VERSION "1.2"

CM_ "TM-630 for Truma interface and Onan Generator
Author: Damiano Liviero
for Winnebago Industries Inc.
";

NS_ :

BS_:
BU_:

CM_ "EF64";
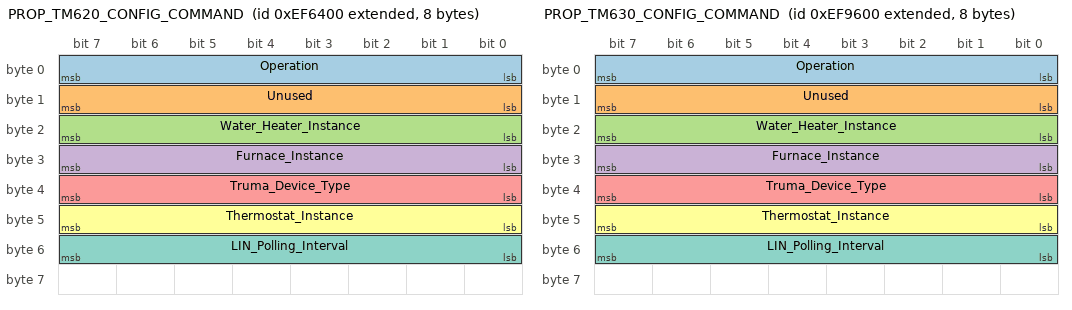
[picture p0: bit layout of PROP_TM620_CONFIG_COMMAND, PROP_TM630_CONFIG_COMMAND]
BO_ 2163172352 PROP_TM620_CONFIG_COMMAND: 8  Vector__XXX
    SG_ Operation:        0|8@1+  (1,0)   [0|255] ""    Vector__XXX
    SG_ Unused:        8|8@1+  (1,0)   [0|255] ""    Vector__XXX
    SG_ Water_Heater_Instance:        16|8@1+  (1,0)   [0|255] ""    Vector__XXX
    SG_ Furnace_Instance:        24|8@1+  (1,0)   [0|255] ""    Vector__XXX
    SG_ Truma_Device_Type:        32|8@1+  (1,0)   [0|255] ""    Vector__XXX
    SG_ Thermostat_Instance:        40|8@1+  (1,0)   [0|255] ""    Vector__XXX
    SG_ LIN_Polling_Interval:        48|8@1+  (1,0)   [0|255] ""    Vector__XXX

    50 "always use"
    255 "Data Invalid";

    255 "Data Invalid";

    255 "Data Invalid";

    255 "Data Invalid";

    0 "AquaGo/VarioHeat"
    1 "Combi"
    255 "Data Invalid";

    255 "Data Invalid";

    1 "100ms"
    2 "200ms"
    3 "300ms"
    4 "400ms"
    5 "500ms"
    255 "Data Invalid";

CM_ "EF96";
BO_ 2163185152 PROP_TM630_CONFIG_COMMAND: 8  Vector__XXX
    SG_ Operation:        0|8@1+  (1,0)   [0|255] ""    Vector__XXX
    SG_ Unused:        8|8@1+  (1,0)   [0|255] ""    Vector__XXX
    SG_ Water_Heater_Instance:        16|8@1+  (1,0)   [0|255] ""    Vector__XXX
    SG_ Furnace_Instance:        24|8@1+  (1,0)   [0|255] ""    Vector__XXX
    SG_ Truma_Device_Type:        32|8@1+  (1,0)   [0|255] ""    Vector__XXX
    SG_ Thermostat_Instance:        40|8@1+  (1,0)   [0|255] ""    Vector__XXX
    SG_ LIN_Polling_Interval:        48|8@1+  (1,0)   [0|255] ""    Vector__XXX

    50 "always use"
    255 "Data Invalid";

    255 "Data Invalid";

    255 "Data Invalid";

    255 "Data Invalid";

    0 "AquaGo/VarioHeat"
    1 "Combi"
    255 "Data Invalid";

    255 "Data Invalid";

    1 "100ms"
    2 "200ms"
    3 "300ms"
    4 "400ms"
    5 "500ms"
    255 "Data Invalid";

CM_ "EF44";
BO_ 2163164160 PROP_TM620_CONFIG_STATUS: 8  Vector__XXX
    SG_ Operation:
        0|8@1+  (1,0)   [0|255] ""    Vector__XXX
    SG_ Unused:
        8|8@1+  (1,0)   [0|255] ""    Vector__XXX
    SG_ Water_Heater_Instance:
        16|8@1+  (1,0)   [0|255] ""    Vector__XXX
    SG_ Furnace_Instance:
        24|8@1+  (1,0)   [0|255] ""    Vector__XXX
    SG_ Truma_Device_Type:
        32|8@1+  (1,0)   [0|255] ""    Vector__XXX
    SG_ Thermostat_Instance:
        40|8@1+  (1,0)   [0|255] ""    Vector__XXX
    SG_ LIN_Polling_Interval:
        48|8@1+  (1,0)   [0|255] ""    Vector__XXX
    SG_ LIN_Bus_Connection:
        56|2@1+  (1,0)   [0|3] ""    Vector__XXX
    SG_ Truma_Control_Panel_Status:
        58|2@1+  (1,0)   [0|3] ""    Vector__XXX
    SG_ Truma_Water_Heater_Error:
        60|2@1+  (1,0)   [0|3] ""    Vector__XXX
    SG_ Truma_Furnace_Error:
        62|2@1+  (1,0)   [0|3] ""    Vector__XXX

    51 "Always"
    255 "Data Invalid";

    255 "Data Invalid";

    255 "Data Invalid";

    255 "Data Invalid";

    0 "AquaGo/VarioHeat"
    1 "Combi"
    255 "Data Invalid";

    255 "Data Invalid";

    1 "100ms"
    2 "200ms"
    3 "300ms"
    4 "400ms"
    5 "500ms"
    255 "Data Invalid";

    0 "No"
    1 "Connected"
    3 "Data Invalid";

    0 "Not Busy"
    1 "Busy"
    3 "Data Invalid";

    0 "Ok"
    1 "Error"
    3 "Data Invalid";

    0 "Ok"
    1 "Error"
    3 "Data Invalid";
